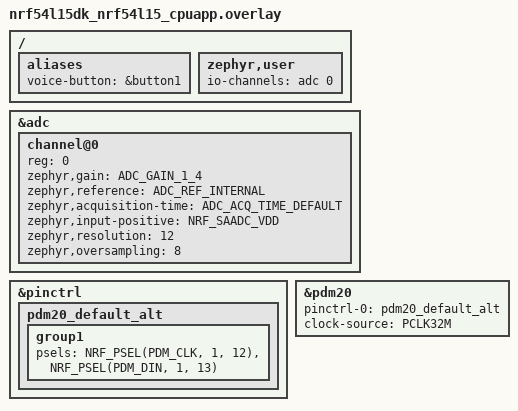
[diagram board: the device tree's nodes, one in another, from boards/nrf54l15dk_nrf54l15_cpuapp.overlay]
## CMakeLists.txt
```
cmake_minimum_required(VERSION 3.20.0)

find_package(Zephyr REQUIRED HINTS $ENV{ZEPHYR_BASE})
project(mi_remote_voice_remote)

target_sources(app PRIVATE
  src/main.c
  src/hid.c
  src/atvv_service.c
  src/audio.c
  src/battery.c
  src/battery_level.c
  src/remote_sm.c
  src/atvv_proto.c
  src/adpcm.c
  src/wake.c
)
```

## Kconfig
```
menu "MiRemoteVoice remote"

choice APP_AUDIO_SOURCE
	prompt "Audio source"
	default APP_AUDIO_SOURCE_TONE

config APP_AUDIO_SOURCE_TONE
	bool "1 kHz test tone"
	help
	  Stream a generated tone instead of the microphone. Useful for
	  checking the Bluetooth and ADPCM path on a board without a mic.

config APP_AUDIO_SOURCE_DMIC
	bool "PDM microphone (pdm20)"
	select AUDIO
	select AUDIO_DMIC

endchoice

config APP_MIC_GAIN_SHIFT
	int "Digital gain applied to microphone samples (left shift)"
	depends on APP_AUDIO_SOURCE_DMIC
	range 0 4
	default 0
	help
	  Note that mi-remote-bridge already amplifies remote audio by
	  +20 dB, so a loud microphone clips without any extra gain here.

config APP_ATVV_FRAME_SIZE
	int "ADPCM bytes per audio notification"
	range 20 244
	default 120
	help
	  Advertised to the host in the capabilities response. The actual
	  notification size is also limited by the negotiated ATT MTU.

config APP_AUDIO_TRANSFER_TIMEOUT_SECONDS
	int "Audio Transfer Timeout (s)"
	range 15 60
	default 20
	help
	  Voice over BLE spec: stop the stream if the host sends no MIC_EXTEND
	  for this long (recommended 15 s to 1 min). mi-remote-bridge sends
	  MIC_EXTEND every 4 s, Android TV every 5-10 s.

config APP_STREAM_MAX_SECONDS
	int "Maximum length of a single voice stream (s)"
	default 120
	help
	  Hard cap, e.g. for a stuck button while the host keeps extending.

config APP_ACTIVE_REMOTE_TIMEOUT_SECONDS
	int "Active Remote Timeout (s), 0 to disable"
	default 60
	help
	  Voice over BLE spec (privacy): a host MIC_OPEN is refused unless the
	  voice button was pressed within this time. Only affects hosts using
	  the On-request model; Hold-to-Talk always requires a press anyway.

config APP_BUTTON_DEBOUNCE_MS
	int "Voice button debounce time (ms)"
	default 15

config APP_AUDIO_THREAD_STACK_SIZE
	int "Audio thread stack size"
	default 2048

config APP_AUDIO_THREAD_PRIORITY
	int "Audio thread priority"
	default 5

menu "Power"

config APP_ADV_FAST_SECONDS
	int "Fast advertising after boot, disconnect or a press (s)"
	default 30

config APP_POWEROFF
	bool "Enter System OFF when idle and disconnected"
	default y
	select POWEROFF
	help
	  The voice button wakes the remote (it resets and reconnects, so the
	  waking press itself is not delivered).

config APP_POWEROFF_IDLE_SECONDS
	int "Disconnected time before System OFF (s)"
	depends on APP_POWEROFF
	default 300

endmenu

menu "Wake press"

config APP_WAKE_CAPTURE
	bool "Record and deliver the press that wakes the remote"
	default y
	help
	  If the voice button is still down when the firmware starts (it woke
	  from System OFF), record audio while reconnecting and deliver it
	  once the host is ready. See src/wake.h.

# The options below stay defined when APP_WAKE_CAPTURE is off so the code
# using them still compiles.

config APP_WAKE_BUFFER_MS
	int "Backlog length (ms)"
	range 500 5000
	default 2000
	help
	  Newest audio kept while reconnecting (8 bytes of RAM per ms).
	  mi-remote-bridge queues at most 2 s of audio, so more is not useful
	  with it.

config APP_WAKE_MIN_REPLAY_MS
	int "Minimum recording to replay a released wake press (ms)"
	default 400
	help
	  Shorter presses are treated as a tap that only wakes the remote.

config APP_WAKE_ROUTE_DELAY_MS
	int "Delay between AUDIO_START and sending the backlog (ms)"
	default 400
	help
	  mi-remote-bridge routes the remote microphone only after the key has
	  been held for 300 ms and drops audio received before that.

config APP_WAKE_TIMEOUT_SECONDS
	int "Give up if the host is not ready within (s)"
	default 10

endmenu

menu "Battery"

choice APP_BATTERY_CURVE
	prompt "Battery voltage to percentage mapping"
	default APP_BATTERY_CURVE_LINEAR

config APP_BATTERY_CURVE_LIPO
	bool "Single-cell LiPo (3.3-4.2 V)"

config APP_BATTERY_CURVE_LINEAR
	bool "Linear between APP_BATTERY_EMPTY_MV and APP_BATTERY_FULL_MV"

endchoice

config APP_BATTERY_EMPTY_MV
	int "Voltage reported as 0 %"
	depends on APP_BATTERY_CURVE_LINEAR
	default 2000

config APP_BATTERY_FULL_MV
	int "Voltage reported as 100 %"
	depends on APP_BATTERY_CURVE_LINEAR
	default 3000

config APP_BATTERY_INTERVAL_SECONDS
	int "Battery measurement interval (s)"
	default 600

endmenu

config APP_PRODUCTION_BUILD
	bool "Production build checks"
	help
	  Fail the build if the Device Information PnP VID/PID are still
	  Nordic's sample IDs.

module = APP
module-str = MiRemoteVoice remote
source "subsys/logging/Kconfig.template.log_config"

endmenu

source "Kconfig.zephyr"
```

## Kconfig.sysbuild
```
# Single-image application: no MCUboot or partition manager for now.
config PARTITION_MANAGER
	default n

source "share/sysbuild/Kconfig"
```

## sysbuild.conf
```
# MCUboot for firmware updates over Bluetooth (MCUmgr / nRF Connect Device
# Manager app).
SB_CONFIG_BOOTLOADER_MCUBOOT=y

# IMPORTANT: without this MCUboot uses the public development key from the
# MCUboot repository, so anyone could sign firmware for your remote. Generate
# your own key once and keep it private:
#   python3 <ncs>/bootloader/mcuboot/scripts/imgtool.py keygen -k priv.pem -t ed25519
# then uncomment:
# SB_CONFIG_BOOT_SIGNATURE_KEY_FILE="\${APPLICATION_CONFIG_DIR}/keys/priv.pem"
```

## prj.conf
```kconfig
# ---- Application ----
CONFIG_GPIO=y
CONFIG_ADC=y
CONFIG_LOG=y
CONFIG_APP_LOG_LEVEL_INF=y
CONFIG_MAIN_STACK_SIZE=3584
CONFIG_SYSTEM_WORKQUEUE_STACK_SIZE=2048

# ---- Bluetooth LE peripheral ----
CONFIG_BT=y
CONFIG_BT_PERIPHERAL=y
CONFIG_BT_MAX_CONN=1
CONFIG_BT_MAX_PAIRED=2
CONFIG_BT_SMP=y
CONFIG_BT_DEVICE_NAME="MiRemoteVoice"
# 961 = HID Keyboard
CONFIG_BT_DEVICE_APPEARANCE=961

# Same workaround as NCS peripheral_hids_keyboard: some laptop controllers
# collide with automatic PHY updates / security requests and disconnect.
CONFIG_BT_GATT_AUTO_SEC_REQ=n
CONFIG_BT_AUTO_PHY_UPDATE=n

# Bonds survive reboots. ZMS is the recommended settings store for the
# nRF54L RRAM; without an explicit backend Zephyr falls back to
# SETTINGS_NONE and the Mac would have to re-pair after every reset.
CONFIG_BT_SETTINGS=y
CONFIG_SETTINGS=y
CONFIG_FLASH=y
CONFIG_FLASH_MAP=y
CONFIG_ZMS=y
CONFIG_SETTINGS_ZMS=y

# Throughput for 8 kB/s of ADPCM: large MTU and data length.
CONFIG_BT_L2CAP_TX_MTU=247
CONFIG_BT_BUF_ACL_TX_SIZE=251
CONFIG_BT_BUF_ACL_RX_SIZE=251
CONFIG_BT_BUF_ACL_TX_COUNT=10
# Must exceed the ACL TX buffer count (static assert in the host).
CONFIG_BT_BUF_EVT_RX_COUNT=16
CONFIG_BT_ATT_TX_COUNT=10
CONFIG_BT_CTLR_DATA_LENGTH_MAX=251

# ---- HID over GATT (voice key) ----
CONFIG_BT_HIDS=y
CONFIG_BT_HIDS_INPUT_REP_MAX=1
CONFIG_BT_HIDS_OUTPUT_REP_MAX=1
CONFIG_BT_HIDS_FEATURE_REP_MAX=0
CONFIG_BT_HIDS_ATTR_MAX=21
CONFIG_BT_HIDS_MAX_CLIENT_COUNT=1
CONFIG_BT_HIDS_DEFAULT_PERM_RW_ENCRYPT=y
CONFIG_BT_CONN_CTX=y
CONFIG_BT_GATT_UUID16_POOL_SIZE=40
CONFIG_BT_GATT_CHRC_POOL_SIZE=20

CONFIG_BT_BAS=y

CONFIG_BT_DIS=y
CONFIG_BT_DIS_MANUF_NAME=y
CONFIG_BT_DIS_MANUF_NAME_STR="MiRemoteVoice"
CONFIG_BT_DIS_PNP=y
# USB-IF vendor ID source. 0x1915/0xEEEF are Nordic's sample IDs, fine for
# development only: replace with your own VID/PID before shipping.
CONFIG_BT_DIS_PNP_VID_SRC=2
CONFIG_BT_DIS_PNP_VID=0x1915
CONFIG_BT_DIS_PNP_PID=0xEEEF
CONFIG_BT_DIS_PNP_VER=0x0100

# ---- Firmware update over Bluetooth (MCUmgr SMP, needs MCUboot) ----
# MCUboot is enabled in sysbuild.conf. Only encrypted (paired) links may use
# the SMP service; MCUboot additionally rejects images not signed with the
# key configured in sysbuild.conf.
CONFIG_NCS_SAMPLE_MCUMGR_BT_OTA_DFU=y
CONFIG_MCUMGR_TRANSPORT_BT_PERM_RW_ENCRYPT=y
```

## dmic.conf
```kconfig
# Use the PDM microphone instead of the test tone:
#   west build ... -- -DEXTRA_CONF_FILE=dmic.conf
CONFIG_APP_AUDIO_SOURCE_DMIC=y
```

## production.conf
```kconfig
# Production build: use together with release.conf
#   west build ... -- -DEXTRA_CONF_FILE="release.conf;production.conf"
#
# The build fails until the USB-IF VID/PID below are replaced with IDs you
# own (the defaults in prj.conf are Nordic's sample IDs).
CONFIG_APP_PRODUCTION_BUILD=y
# CONFIG_BT_DIS_PNP_VID=0x....
# CONFIG_BT_DIS_PNP_PID=0x....
# CONFIG_BT_DIS_MANUF_NAME_STR="Your Company"
```

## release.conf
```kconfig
# Low-power release build: no logging or UART console (a running UART
# receiver costs hundreds of uA).
#   west build ... -- -DEXTRA_CONF_FILE=release.conf
CONFIG_LOG=n
CONFIG_SERIAL=n
CONFIG_CONSOLE=n
CONFIG_UART_CONSOLE=n
```

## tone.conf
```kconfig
# Force the 1 kHz test tone (e.g. on a XIAO without the Sense microphone).
CONFIG_APP_AUDIO_SOURCE_TONE=y
```

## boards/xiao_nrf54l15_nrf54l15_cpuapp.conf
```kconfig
# The XIAO nRF54L15 Sense has an on-board PDM microphone.
# For the plain XIAO nRF54L15 (no mic), build with -DEXTRA_CONF_FILE=tone.conf.
CONFIG_APP_AUDIO_SOURCE_DMIC=y

# Single-cell LiPo on the BAT pads.
CONFIG_APP_BATTERY_CURVE_LIPO=y
```

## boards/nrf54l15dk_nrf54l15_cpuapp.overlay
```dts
/*
 * nRF54L15 DK: the voice key is BUTTON 1 (P1.09) because BUTTON 0 (P1.13)
 * shares a pin with the external PDM microphone below.
 *
 * External PDM mic wiring (same pins as Zephyr's DMIC sample):
 *   CLK -> P1.12, DATA -> P1.13, plus VDD/GND and L/R select to GND (left).
 * Change the psels to match your wiring.
 */
/ {
	aliases {
		voice-button = &button1;
	};

	/* Battery level = supply voltage (VDD), as on a remote running directly
	 * from 2x AAA. On the DK this is the regulated VDD, not a battery. */
	zephyr,user {
		io-channels = <&adc 0>;
	};
};

&adc {
	#address-cells = <1>;
	#size-cells = <0>;
	status = "okay";

	channel@0 {
		reg = <0>;
		zephyr,gain = "ADC_GAIN_1_4";
		zephyr,reference = "ADC_REF_INTERNAL";
		zephyr,acquisition-time = <ADC_ACQ_TIME_DEFAULT>;
		zephyr,input-positive = <NRF_SAADC_VDD>;
		zephyr,resolution = <12>;
		zephyr,oversampling = <8>;
	};
};

&pinctrl {
	pdm20_default_alt: pdm20_default_alt {
		group1 {
			psels = <NRF_PSEL(PDM_CLK, 1, 12)>,
				<NRF_PSEL(PDM_DIN, 1, 13)>;
		};
	};
};

&pdm20 {
	status = "okay";
	pinctrl-0 = <&pdm20_default_alt>;
	pinctrl-names = "default";
	clock-source = "PCLK32M";
};
```

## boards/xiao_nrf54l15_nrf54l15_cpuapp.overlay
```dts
/*
 * Seeed XIAO nRF54L15 (Sense): the voice key is the USR button (alias sw0);
 * the Sense microphone (pdm20) is already described by the board.
 *
 * Battery: VBAT is read on AIN7 through a 2:1 divider that is switched on
 * by the vbat_pwr regulator (P1.15) only while measuring.
 */
/ {
	zephyr,user {
		io-channels = <&adc 7>;
		battery-divider-ratio = <2>;
		battery-enable = <&vbat_pwr>;
	};
};
```

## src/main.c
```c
/*
 * MiRemoteVoice nRF54L15 voice remote.
 *
 * A BLE HID keyboard (voice key = F5) plus the Android TV Voice (ATVV) service
 * streaming 16 kHz IMA ADPCM, compatible with mi-remote-bridge on macOS.
 *
 * Threads:
 *   main  - owns the remote_sm state machine; all events arrive via app_events
 *   audio - reads the mic (or test tone), encodes and notifies audio frames
 *
 * Power: between presses the SoC idles in System ON sleep. While
 * disconnected it advertises fast, then slowly, and finally enters System OFF
 * (a few uA); the voice button wakes it with a reset. Audio spoken while it
 * reconnects is recorded and delivered once the host is ready (wake.h).
 */
#include <string.h>

#include <zephyr/bluetooth/bluetooth.h>
#include <zephyr/bluetooth/conn.h>
#include <zephyr/bluetooth/gatt.h>
#include <zephyr/bluetooth/uuid.h>
#include <zephyr/drivers/gpio.h>
#include <zephyr/kernel.h>
#include <zephyr/logging/log.h>
#include <zephyr/logging/log_ctrl.h>
#include <zephyr/settings/settings.h>
#include <zephyr/spinlock.h>
#include <zephyr/sys/poweroff.h>

#include "app.h"
#include "atvv_proto.h"
#include "atvv_service.h"
#include "audio.h"
#include "battery.h"
#include "hid.h"
#include "remote_sm.h"
#include "wake.h"

LOG_MODULE_REGISTER(app, CONFIG_APP_LOG_LEVEL);

#if defined(CONFIG_APP_PRODUCTION_BUILD)
BUILD_ASSERT(CONFIG_BT_DIS_PNP_VID != 0x1915 || CONFIG_BT_DIS_PNP_PID != 0xEEEF,
	     "Production build still uses Nordic's sample USB VID/PID: set "
	     "CONFIG_BT_DIS_PNP_VID/PID to your own IDs (see production.conf)");
#endif

/* ---- Connection tracking. ---- */

static struct k_spinlock conn_lock;
static struct bt_conn *current_conn;

struct bt_conn *app_conn_get(void)
{
	k_spinlock_key_t key = k_spin_lock(&conn_lock);
	struct bt_conn *conn = current_conn ? bt_conn_ref(current_conn) : NULL;

	k_spin_unlock(&conn_lock, key);
	return conn;
}

void app_conn_put(struct bt_conn *conn)
{
	if (conn) {
		bt_conn_unref(conn);
	}
}

/* ---- Events for the main thread. ---- */

enum app_event_type {
	EVT_BUTTON,         /* data[0] = pressed */
	EVT_HOST_WRITE,     /* data = ATVV command */
	EVT_AUDIO_CCC,      /* data[0] = notifications enabled */
	EVT_TIMEOUT,        /* data[0] = enum remote_timeout */
	EVT_INACTIVE,       /* Active Remote Timeout expired */
	EVT_DISCONNECTED,
	EVT_SECURITY,       /* link encrypted */
	EVT_WAKE_TIMEOUT,   /* host not ready in time for the wake press */
	EVT_BACKLOG_SENT,   /* wake backlog sent (or abandoned) */
};

struct app_event {
	uint8_t type;
	uint8_t len;
	uint8_t data[8];
};

K_MSGQ_DEFINE(app_events, sizeof(struct app_event), 16, 4);

static void post_event(const struct app_event *evt)
{
	if (k_msgq_put(&app_events, evt, K_NO_WAIT)) {
		LOG_WRN("event queue full, dropped type %u", evt->type);
	}
}

/* ---- Voice button (debounced GPIO) and LED. ---- */

#if DT_NODE_HAS_STATUS(DT_ALIAS(voice_button), okay)
#define BUTTON_NODE DT_ALIAS(voice_button)
#else
#define BUTTON_NODE DT_ALIAS(sw0)
#endif

static const struct gpio_dt_spec button = GPIO_DT_SPEC_GET(BUTTON_NODE, gpios);
static const struct gpio_dt_spec led = GPIO_DT_SPEC_GET_OR(DT_ALIAS(led0), gpios, {0});
static struct gpio_callback button_cb;
static bool button_reported;

static void button_debounced(struct k_work *work)
{
	bool pressed = gpio_pin_get_dt(&button) > 0;

	if (pressed == button_reported) {
		return;
	}
	button_reported = pressed;
	post_event(&(struct app_event){.type = EVT_BUTTON, .data = {pressed}});
}

static K_WORK_DELAYABLE_DEFINE(button_work, button_debounced);

static void button_isr(const struct device *dev, struct gpio_callback *cb, uint32_t pins)
{
	k_work_reschedule(&button_work, K_MSEC(CONFIG_APP_BUTTON_DEBOUNCE_MS));
}

static int button_init(void)
{
	int err;

	if (!gpio_is_ready_dt(&button)) {
		return -ENODEV;
	}
	err = gpio_pin_configure_dt(&button, GPIO_INPUT);
	if (!err) {
		/* A press that is still down at boot is the one that woke us. */
		button_reported = gpio_pin_get_dt(&button) > 0;

		err = gpio_pin_interrupt_configure_dt(&button, GPIO_INT_EDGE_BOTH);
	}
	if (err) {
		return err;
	}
	gpio_init_callback(&button_cb, button_isr, BIT(button.pin));
	gpio_add_callback(button.port, &button_cb);

	if (led.port && gpio_is_ready_dt(&led)) {
		gpio_pin_configure_dt(&led, GPIO_OUTPUT_INACTIVE);
	}
	return 0;
}

static void set_led(bool on)
{
	if (led.port) {
		gpio_pin_set_dt(&led, on);
	}
}

/* ---- Advertising and power policy (system workqueue). ---- */

#define ATVV_SERVICE_UUID                                                                          \
	BT_UUID_128_ENCODE(ATVV_UUID_SERVICE_VAL, 0x5A21, 0x4F05, 0xBC7D, 0xAF01F617B664ULL)

/* The bridge finds the remote by the ATVV UUID in the advertisement. */
static const struct bt_data ad[] = {
	BT_DATA_BYTES(BT_DATA_FLAGS, (BT_LE_AD_GENERAL | BT_LE_AD_NO_BREDR)),
	BT_DATA_BYTES(BT_DATA_GAP_APPEARANCE, (CONFIG_BT_DEVICE_APPEARANCE >> 0) & 0xff,
		      (CONFIG_BT_DEVICE_APPEARANCE >> 8) & 0xff),
	BT_DATA_BYTES(BT_DATA_UUID16_SOME, BT_UUID_16_ENCODE(BT_UUID_HIDS_VAL)),
	BT_DATA_BYTES(BT_DATA_UUID128_SOME, ATVV_SERVICE_UUID),
};

static const struct bt_data sd[] = {
	BT_DATA(BT_DATA_NAME_COMPLETE, CONFIG_BT_DEVICE_NAME, sizeof(CONFIG_BT_DEVICE_NAME) - 1),
};

static bool is_connected(void)
{
	struct bt_conn *conn = app_conn_get();
	bool connected = conn != NULL;

	app_conn_put(conn);
	return connected;
}

static void advertise(bool fast)
{
	/* Fast: quick reconnection right after boot, disconnect or a press.
	 * Slow: cheap background advertising until System OFF. */
	const struct bt_le_adv_param *param =
		fast ? BT_LE_ADV_PARAM(BT_LE_ADV_OPT_CONN, BT_GAP_ADV_FAST_INT_MIN_1,
				       BT_GAP_ADV_FAST_INT_MAX_1, NULL)
		     : BT_LE_ADV_PARAM(BT_LE_ADV_OPT_CONN, BT_GAP_ADV_SLOW_INT_MIN,
				       BT_GAP_ADV_SLOW_INT_MAX, NULL);

	(void)bt_le_adv_stop();
	int err = bt_le_adv_start(param, ad, ARRAY_SIZE(ad), sd, ARRAY_SIZE(sd));

	if (err) {
		LOG_ERR("advertising failed: %d", err);
		return;
	}
	LOG_INF("advertising (%s)", fast ? "fast" : "slow");
}

static void adv_slow_handler(struct k_work *work)
{
	if (!is_connected()) {
		advertise(false);
	}
}

static K_WORK_DELAYABLE_DEFINE(adv_slow_work, adv_slow_handler);

static void poweroff_handler(struct k_work *work);
static K_WORK_DELAYABLE_DEFINE(poweroff_work, poweroff_handler);

/* Start (or restart) the disconnected-state timeline: fast -> slow -> off. */
static void disconnected_timeline(struct k_work *work)
{
	if (is_connected()) {
		return;
	}
	advertise(true);
	k_work_reschedule(&adv_slow_work, K_SECONDS(CONFIG_APP_ADV_FAST_SECONDS));
	if (IS_ENABLED(CONFIG_APP_POWEROFF) && CONFIG_APP_POWEROFF_IDLE_SECONDS > 0) {
		k_work_reschedule(&poweroff_work, K_SECONDS(CONFIG_APP_POWEROFF_IDLE_SECONDS));
	}
}

static K_WORK_DEFINE(timeline_work, disconnected_timeline);

static void stop_disconnected_timeline(void)
{
	k_work_cancel_delayable(&adv_slow_work);
	k_work_cancel_delayable(&poweroff_work);
}

static void poweroff_handler(struct k_work *work)
{
#if defined(CONFIG_APP_POWEROFF)
	if (is_connected()) {
		return;
	}
	LOG_INF("idle while disconnected: entering System OFF, press the voice button to wake");
	(void)bt_le_adv_stop();
	audio_stop();
	set_led(false);

	/* Level-sensitive wake-up on the voice button. */
	int err = gpio_pin_interrupt_configure_dt(&button, GPIO_INT_LEVEL_ACTIVE);

	if (err) {
		LOG_ERR("cannot arm wake-up button (%d), staying on", err);
		gpio_pin_interrupt_configure_dt(&button, GPIO_INT_EDGE_BOTH);
		return;
	}
	if (IS_ENABLED(CONFIG_LOG)) {
		log_panic(); /* flush pending log output */
	}
	sys_poweroff();
#endif
}

/* ---- Timers owned by the state machine glue. ---- */

static void transfer_timeout(struct k_work *work)
{
	post_event(&(struct app_event){.type = EVT_TIMEOUT, .data = {REMOTE_TIMEOUT_TRANSFER}});
}

static void max_duration_timeout(struct k_work *work)
{
	post_event(&(struct app_event){.type = EVT_TIMEOUT, .data = {REMOTE_TIMEOUT_MAX}});
}

static void active_timeout(struct k_work *work)
{
	post_event(&(struct app_event){.type = EVT_INACTIVE});
}

/* Spec "Audio Transfer Timeout": reset by AUDIO_START and MIC_EXTEND. */
static K_WORK_DELAYABLE_DEFINE(transfer_work, transfer_timeout);
/* Hard cap on stream length in case the button is stuck. */
static K_WORK_DELAYABLE_DEFINE(max_duration_work, max_duration_timeout);
/* Spec "Active Remote Timeout": MIC_OPEN only shortly after user activity. */
static K_WORK_DELAYABLE_DEFINE(active_work, active_timeout);

static void wake_timeout_handler(struct k_work *work)
{
	post_event(&(struct app_event){.type = EVT_WAKE_TIMEOUT});
}

static K_WORK_DELAYABLE_DEFINE(wake_timeout_work, wake_timeout_handler);

/* ---- State machine glue (runs on the main thread). ---- */

static struct remote_sm sm;
static struct wake wake;
/* The next AUDIO_START belongs to the wake press: send its backlog instead
 * of starting a fresh recording. */
static bool wake_stream_pending;
/* The wake backlog is waiting to be sent (route delay). */
static bool wake_backlog_inflight;
/* The button is already up: release the delivered press once the backlog has
 * been sent. */
static bool wake_replaying;

static void sm_send_ctl(void *ctx, const uint8_t *data, size_t len)
{
	struct bt_conn *conn = app_conn_get();
	int err = atvv_notify_ctl(conn, data, len);

	if (err && conn) {
		LOG_WRN("ctl 0x%02x not sent: %d", data[0], err);
	}
	app_conn_put(conn);
}

static void sm_hid_key(void *ctx, bool pressed)
{
	struct bt_conn *conn = app_conn_get();
	int err = hid_voice_key(conn, pressed);

	if (err && conn) {
		LOG_WRN("HID key %s not sent: %d", pressed ? "down" : "up", err);
	}
	app_conn_put(conn);
}

static void sm_audio_start(void *ctx, uint8_t codec, uint16_t frame_size)
{
	k_work_reschedule(&max_duration_work, K_SECONDS(CONFIG_APP_STREAM_MAX_SECONDS));
	set_led(true);
	if (wake_stream_pending) {
		wake_stream_pending = false;
		/* Hold the backlog back until the bridge has classified the press
		 * as a long press and routed the remote mic (300 ms); audio before
		 * that would be dropped on the Mac. */
		wake_backlog_inflight = true;
		audio_prebuffer_release(CONFIG_APP_WAKE_ROUTE_DELAY_MS);
	} else {
		audio_start(codec, frame_size);
	}
}

static void sm_audio_stop(void *ctx)
{
	if (wake_backlog_inflight) {
		/* Stream ended (timeout, MIC_CLOSE...) before the backlog went
		 * out: the audio thread will not report it, so do it here so a
		 * replayed press still gets released. */
		post_event(&(struct app_event){.type = EVT_BACKLOG_SENT});
	}
	audio_stop();
	set_led(false);
	k_work_cancel_delayable(&max_duration_work);
}

static void sm_transfer_timer(void *ctx, bool arm)
{
	if (arm) {
		k_work_reschedule(&transfer_work,
				  K_SECONDS(CONFIG_APP_AUDIO_TRANSFER_TIMEOUT_SECONDS));
	} else {
		k_work_cancel_delayable(&transfer_work);
	}
}

static void sm_user_activity(void *ctx)
{
	if (CONFIG_APP_ACTIVE_REMOTE_TIMEOUT_SECONDS > 0) {
		k_work_reschedule(&active_work, K_SECONDS(CONFIG_APP_ACTIVE_REMOTE_TIMEOUT_SECONDS));
	}
}

static const struct remote_sm_ops sm_ops = {
	.send_ctl = sm_send_ctl,
	.hid_key = sm_hid_key,
	.audio_start = sm_audio_start,
	.audio_stop = sm_audio_stop,
	.transfer_timer = sm_transfer_timer,
	.user_activity = sm_user_activity,
};

/* Keep the state machine's view of the link current before each event. */
static void refresh_link_state(void)
{
	struct bt_conn *conn = app_conn_get();

	if (conn) {
		uint16_t mtu = bt_gatt_get_mtu(conn);
		uint16_t max = CONFIG_APP_ATVV_FRAME_SIZE;

		if (mtu > 3 && mtu - 3 < max) {
			max = mtu - 3;
		}
		remote_sm_set_max_frame_size(&sm, max);
		remote_sm_audio_subscribed(&sm, atvv_audio_subscribed(conn));
	}
	app_conn_put(conn);
}

/* Bluetooth RX thread: copy the command and hand it to the main thread. */
static void on_atvv_write(const uint8_t *data, size_t len)
{
	struct app_event evt = {.type = EVT_HOST_WRITE};

	evt.len = (uint8_t)MIN(len, sizeof(evt.data));
	memcpy(evt.data, data, evt.len);
	post_event(&evt);
}

static void on_audio_ccc(bool enabled)
{
	post_event(&(struct app_event){.type = EVT_AUDIO_CCC, .data = {enabled}});
}

/* Audio thread: the wake backlog has been sent. */
static void on_backlog_sent(bool recording)
{
	ARG_UNUSED(recording);
	post_event(&(struct app_event){.type = EVT_BACKLOG_SENT});
}

/* ---- Wake press (runs on the main thread). ---- */

static const char *const wake_action_names[] = {
	"none", "freeze", "restart", "deliver hold", "deliver replay", "deliver press", "discard",
};

/* Deliver the wake press to the state machine as a (replayed) press. */
static void deliver_wake_press(bool replay)
{
	wake_stream_pending = true;
	wake_replaying = replay;
	remote_sm_button(&sm, true);

	if (wake_stream_pending) {
		/* No stream started (e.g. notifications went away): give up. */
		wake_stream_pending = false;
		audio_stop();
		if (replay) {
			wake_replaying = false;
			remote_sm_button(&sm, false);
		}
	}
}

static void apply_wake_action(enum wake_action action)
{
	if (action == WAKE_NONE) {
		return;
	}
	LOG_INF("wake press: %s (backlog %u ms)", wake_action_names[action], audio_backlog_ms());

	switch (action) {
	case WAKE_FREEZE:
		audio_prebuffer_freeze();
		break;
	case WAKE_RESTART:
		audio_prebuffer_start();
		break;
	case WAKE_DELIVER_HOLD:
		deliver_wake_press(false);
		break;
	case WAKE_DELIVER_REPLAY:
		deliver_wake_press(true);
		break;
	case WAKE_DELIVER_PRESS:
		audio_stop();
		remote_sm_button(&sm, true);
		break;
	case WAKE_DISCARD:
		audio_stop();
		break;
	default:
		break;
	}

	if (!wake_pending(&wake)) {
		k_work_cancel_delayable(&wake_timeout_work);
	}
}

/* Deliver the wake press once the host can take it. */
static void check_wake_ready(void)
{
	if (!wake_pending(&wake)) {
		return;
	}

	struct bt_conn *conn = app_conn_get();
	bool ready = conn && bt_conn_get_security(conn) >= BT_SECURITY_L2 && sm.caps_received &&
		     sm.audio_subscribed;

	app_conn_put(conn);
	if (ready) {
		apply_wake_action(wake_ready(&wake, sm.model == ATVV_MODEL_HOLD_TO_TALK,
					     audio_backlog_ms()));
	}
}

/* ---- Connection callbacks. ---- */

static void connected(struct bt_conn *conn, uint8_t err)
{
	if (err) {
		LOG_WRN("connection failed: 0x%02x", err);
		return;
	}

	k_spinlock_key_t key = k_spin_lock(&conn_lock);

	if (current_conn) {
		/* CONFIG_BT_MAX_CONN=1 should make this unreachable. */
		k_spin_unlock(&conn_lock, key);
		bt_conn_disconnect(conn, BT_HCI_ERR_REMOTE_USER_TERM_CONN);
		return;
	}
	current_conn = bt_conn_ref(conn);
	k_spin_unlock(&conn_lock, key);

	LOG_INF("connected");
	stop_disconnected_timeline();
	hid_connected(conn);
	battery_measure();

	/* 7.5-15 ms while there is traffic; peripheral latency lets the radio
	 * skip up to 30 idle intervals between presses. */
	struct bt_le_conn_param param = BT_LE_CONN_PARAM_INIT(6, 12, 30, 400);

	bt_conn_le_param_update(conn, &param);
}

static void disconnected(struct bt_conn *conn, uint8_t reason)
{
	LOG_INF("disconnected: 0x%02x", reason);
	hid_disconnected(conn);

	k_spinlock_key_t key = k_spin_lock(&conn_lock);

	if (current_conn == conn) {
		bt_conn_unref(current_conn);
		current_conn = NULL;
	}
	k_spin_unlock(&conn_lock, key);

	post_event(&(struct app_event){.type = EVT_DISCONNECTED});
}

static void recycled(void)
{
	k_work_submit(&timeline_work);
}

static void security_changed(struct bt_conn *conn, bt_security_t level, enum bt_security_err err)
{
	if (err) {
		LOG_WRN("security failed: level %u err %d", level, err);
	} else {
		LOG_INF("security level %u", level);
		post_event(&(struct app_event){.type = EVT_SECURITY});
	}
}

BT_CONN_CB_DEFINE(conn_callbacks) = {
	.connected = connected,
	.disconnected = disconnected,
	.recycled = recycled,
	.security_changed = security_changed,
};

static void handle_event(const struct app_event *evt)
{
	switch (evt->type) {
	case EVT_BUTTON: {
		enum wake_action action;

		LOG_INF("voice button %s", evt->data[0] ? "down" : "up");
		if (evt->data[0] && !is_connected()) {
			/* Pressing while disconnected: advertise fast again and
			 * postpone System OFF. */
			k_work_submit(&timeline_work);
		}
		if (wake_button(&wake, evt->data[0], &action)) {
			apply_wake_action(action);
			break;
		}
		if (!evt->data[0] && wake_backlog_inflight && !wake_replaying) {
			/* Released during the route delay: stop recording, send what
			 * was recorded, then release (EVT_BACKLOG_SENT). */
			audio_prebuffer_freeze();
			wake_replaying = true;
			break;
		}
		refresh_link_state();
		remote_sm_button(&sm, evt->data[0]);
		break;
	}
	case EVT_HOST_WRITE:
		LOG_DBG("host cmd 0x%02x (%u bytes)", evt->data[0], evt->len);
		refresh_link_state();
		remote_sm_host_write(&sm, evt->data, evt->len);
		check_wake_ready();
		break;
	case EVT_AUDIO_CCC:
		remote_sm_audio_subscribed(&sm, evt->data[0]);
		check_wake_ready();
		break;
	case EVT_SECURITY:
		refresh_link_state();
		check_wake_ready();
		break;
	case EVT_WAKE_TIMEOUT:
		apply_wake_action(wake_timeout(&wake));
		break;
	case EVT_BACKLOG_SENT:
		wake_backlog_inflight = false;
		if (wake_replaying) {
			wake_replaying = false;
			remote_sm_button(&sm, false);
		}
		break;
	case EVT_TIMEOUT:
		LOG_WRN("stream timeout (%s)",
			evt->data[0] == REMOTE_TIMEOUT_TRANSFER ? "no MIC_EXTEND" : "max duration");
		remote_sm_timeout(&sm, evt->data[0]);
		break;
	case EVT_INACTIVE:
		remote_sm_set_active(&sm, false);
		break;
	case EVT_DISCONNECTED:
		wake_stream_pending = false;
		wake_backlog_inflight = false;
		wake_replaying = false;
		remote_sm_disconnected(&sm);
		break;
	default:
		break;
	}
}

int main(void)
{
	int err;

	LOG_INF("MiRemoteVoice remote starting");

	err = button_init();
	if (err) {
		LOG_ERR("button init failed: %d", err);
		return 0;
	}

	err = audio_init(on_backlog_sent);
	if (err) {
		LOG_ERR("audio init failed: %d", err);
		return 0;
	}

	wake_init(&wake, IS_ENABLED(CONFIG_APP_WAKE_CAPTURE) && button_reported,
		  CONFIG_APP_WAKE_MIN_REPLAY_MS);
	if (wake_pending(&wake)) {
		LOG_INF("woken by the voice button: recording until the host is ready");
		audio_prebuffer_start();
		k_work_reschedule(&wake_timeout_work, K_SECONDS(CONFIG_APP_WAKE_TIMEOUT_SECONDS));
	}

	remote_sm_init(&sm, &sm_ops, NULL);
	if (CONFIG_APP_ACTIVE_REMOTE_TIMEOUT_SECONDS == 0) {
		remote_sm_set_active(&sm, true); /* timeout disabled */
	}
	atvv_service_init(on_atvv_write, on_audio_ccc);

	err = hid_init();
	if (err) {
		LOG_ERR("HID init failed: %d", err);
		return 0;
	}

	err = bt_enable(NULL);
	if (err) {
		LOG_ERR("bt_enable failed: %d", err);
		return 0;
	}

	if (IS_ENABLED(CONFIG_SETTINGS)) {
		settings_load();
	}

	/* Battery reporting is optional; keep going without it. */
	(void)battery_init();

	k_work_submit(&timeline_work);

	for (;;) {
		struct app_event evt;

		k_msgq_get(&app_events, &evt, K_FOREVER);
		handle_event(&evt);
	}
	return 0;
}
```

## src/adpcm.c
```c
/*
 * IMA/DVI ADPCM encoder. The quantisation and state update mirror
 * mi-remote-bridge/Sources/MiRemoteBridge/ATVV/ADPCMDecoder.swift exactly, so
 * the encoder's predictor always equals the decoder's output sample.
 */
#include "adpcm.h"

static const int8_t index_table[8] = {-1, -1, -1, -1, 2, 4, 6, 8};

static const int16_t step_table[89] = {
	7,     8,     9,     10,    11,    12,    13,    14,    16,    17,    19,    21,    23,
	25,    28,    31,    34,    37,    41,    45,    50,    55,    60,    66,    73,    80,
	88,    97,    107,   118,   130,   143,   157,   173,   190,   209,   230,   253,   279,
	307,   337,   371,   408,   449,   494,   544,   598,   658,   724,   796,   876,   963,
	1060,  1166,  1282,  1411,  1552,  1707,  1878,  2066,  2272,  2494,  2740,  3008,  3307,
	3638,  4002,  4402,  4842,  5327,  5860,  6446,  7091,  7800,  8580,  9438,  10382, 11420,
	12562, 13818, 15200, 16720, 18392, 20231, 22254, 24479, 26927, 29620, 32767,
};

void adpcm_reset(struct adpcm_state *state)
{
	state->predictor = 0;
	state->step_index = 0;
}

uint8_t adpcm_encode_sample(struct adpcm_state *state, int16_t sample)
{
	int step = step_table[state->step_index];
	int diff = (int)sample - (int)state->predictor;
	uint8_t code = 0;

	if (diff < 0) {
		code = 8;
		diff = -diff;
	}

	/* Same reconstruction as the decoder: step/8 + step + step/2 + step/4. */
	int delta = step >> 3;

	if (diff >= step) {
		code |= 4;
		diff -= step;
		delta += step;
	}
	if (diff >= (step >> 1)) {
		code |= 2;
		diff -= step >> 1;
		delta += step >> 1;
	}
	if (diff >= (step >> 2)) {
		code |= 1;
		delta += step >> 2;
	}

	int predictor = state->predictor + ((code & 8) ? -delta : delta);

	if (predictor > INT16_MAX) {
		predictor = INT16_MAX;
	} else if (predictor < INT16_MIN) {
		predictor = INT16_MIN;
	}
	state->predictor = (int16_t)predictor;

	int index = state->step_index + index_table[code & 7];

	if (index < 0) {
		index = 0;
	} else if (index > 88) {
		index = 88;
	}
	state->step_index = (uint8_t)index;

	return code;
}

void adpcm_encode(struct adpcm_state *state, const int16_t *samples, size_t count,
		  uint8_t *out)
{
	for (size_t i = 0; i + 1 < count; i += 2) {
		uint8_t hi = adpcm_encode_sample(state, samples[i]);
		uint8_t lo = adpcm_encode_sample(state, samples[i + 1]);

		out[i / 2] = (uint8_t)((hi << 4) | lo);
	}
}
```

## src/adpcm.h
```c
/*
 * IMA/DVI ADPCM encoder matching mi-remote-bridge's ADPCMDecoder.swift.
 *
 * Portable C with no Zephyr dependencies so it can be unit-tested on the host
 * (see tests/host).
 */
#ifndef ADPCM_H_
#define ADPCM_H_

#include <stddef.h>
#include <stdint.h>

struct adpcm_state {
	int16_t predictor;
	uint8_t step_index;
};

void adpcm_reset(struct adpcm_state *state);

/* Encode one sample and return its 4-bit code. */
uint8_t adpcm_encode_sample(struct adpcm_state *state, int16_t sample);

/*
 * Encode `count` samples (must be even) into count / 2 bytes.
 *
 * Nibble order is HIGH nibble first: byte = (code[n] << 4) | code[n + 1].
 * This is what the Mac bridge decodes; many IMA libraries use the opposite
 * order, so do not swap in a third-party encoder without checking this.
 */
void adpcm_encode(struct adpcm_state *state, const int16_t *samples, size_t count,
		  uint8_t *out);

#endif /* ADPCM_H_ */
```

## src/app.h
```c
/* Shared application state. */
#ifndef APP_H_
#define APP_H_

#include <zephyr/bluetooth/conn.h>

/* Take a reference to the current connection (NULL if none). Always pair with
 * app_conn_put(), which accepts NULL. Safe from any thread. */
struct bt_conn *app_conn_get(void);
void app_conn_put(struct bt_conn *conn);

#endif /* APP_H_ */
```

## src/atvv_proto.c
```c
#include "atvv_proto.h"

#include <string.h>

static void put_be16(uint8_t *buf, uint16_t value)
{
	buf[0] = (uint8_t)(value >> 8);
	buf[1] = (uint8_t)(value & 0xFF);
}

size_t atvv_build_caps_resp(uint8_t *buf, uint8_t codec, uint8_t model, uint16_t frame_size,
			    uint8_t extra_config)
{
	/* 0B | version 1.0 | codecs | interaction model | frame size | extra | rfu */
	buf[0] = ATVV_CTL_GET_CAPS_RESP;
	buf[1] = 0x01;
	buf[2] = 0x00;
	buf[3] = codec;
	buf[4] = model;
	put_be16(&buf[5], frame_size);
	buf[7] = extra_config;
	buf[8] = 0x00;
	return ATVV_CAPS_RESP_LEN;
}

size_t atvv_build_audio_start(uint8_t *buf, uint8_t reason, uint8_t codec, uint8_t stream_id)
{
	buf[0] = ATVV_CTL_AUDIO_START;
	buf[1] = reason;
	buf[2] = codec;
	buf[3] = stream_id;
	return ATVV_AUDIO_START_LEN;
}

size_t atvv_build_audio_sync(uint8_t *buf, uint8_t codec, uint16_t frame_num,
			     const struct adpcm_state *state)
{
	buf[0] = ATVV_CTL_AUDIO_SYNC;
	buf[1] = codec;
	put_be16(&buf[2], frame_num);
	put_be16(&buf[4], (uint16_t)state->predictor);
	buf[6] = state->step_index;
	return ATVV_AUDIO_SYNC_LEN;
}

size_t atvv_build_audio_stop(uint8_t *buf, uint8_t reason)
{
	buf[0] = ATVV_CTL_AUDIO_STOP;
	buf[1] = reason;
	return ATVV_AUDIO_STOP_LEN;
}

size_t atvv_build_start_search(uint8_t *buf)
{
	buf[0] = ATVV_CTL_START_SEARCH;
	return ATVV_START_SEARCH_LEN;
}

size_t atvv_build_mic_open_error(uint8_t *buf, uint16_t code)
{
	buf[0] = ATVV_CTL_MIC_OPEN_ERROR;
	put_be16(&buf[1], code);
	return ATVV_MIC_OPEN_ERR_LEN;
}

struct atvv_cmd atvv_parse_cmd(const uint8_t *data, size_t len)
{
	struct atvv_cmd cmd = {0};

	if (len == 0) {
		return cmd;
	}

	cmd.opcode = data[0];
	switch (cmd.opcode) {
	case ATVV_CMD_GET_CAPS:
		/* version(2) | legacy 0x0003(2) | supported interaction models(1).
		 * Hosts that omit the models field only support On-request. */
		cmd.host_models = len > 5 ? data[5] : ATVV_MODEL_ON_REQUEST;
		cmd.valid = true;
		break;
	case ATVV_CMD_MIC_OPEN:
		cmd.valid = true;
		break;
	case ATVV_CMD_MIC_CLOSE:
	case ATVV_CMD_MIC_EXTEND:
		/* v1.0 carries the stream id; v0.4 hosts send the bare opcode,
		 * which can only mean the current stream. */
		cmd.stream_id = len > 1 ? data[1] : ATVV_STREAM_ID_ANY;
		cmd.valid = true;
		break;
	default:
		break;
	}
	return cmd;
}

void atvv_framer_init(struct atvv_framer *f, const struct atvv_framer_ops *ops, void *ctx)
{
	memset(f, 0, sizeof(*f));
	f->ops = ops;
	f->ctx = ctx;
	f->frame_size = ATVV_FRAME_MAX;
}

void atvv_framer_start(struct atvv_framer *f, uint8_t codec, uint16_t frame_size)
{
	if (frame_size < 1) {
		frame_size = 1;
	} else if (frame_size > ATVV_FRAME_MAX) {
		frame_size = ATVV_FRAME_MAX;
	}

	adpcm_reset(&f->enc);
	f->frame_start = f->enc;
	f->codec = codec;
	f->frame_size = frame_size;
	f->fill = 0;
	f->frame_num = 0;
	f->resync_pending = true;
	f->have_odd = false;
	f->holding = false;
	f->count = 0;
	f->frames_sent = 0;
	f->frames_dropped = 0;
	f->backlog_dropped = 0;
}

/* Send one frame; `start`/`num` describe it for a possible AUDIO_SYNC. */
static void framer_send(struct atvv_framer *f, const uint8_t *data, size_t len,
			const struct adpcm_state *start, uint16_t num)
{
	bool send = true;

	if (f->resync_pending) {
		uint8_t sync[ATVV_AUDIO_SYNC_LEN];
		size_t sync_len = atvv_build_audio_sync(sync, f->codec, num, start);

		if (f->ops->send_ctl(f->ctx, sync, sync_len) == 0) {
			f->resync_pending = false;
		} else {
			/* The host would decode this frame with stale state: drop it
			 * and try the sync again before the next one. */
			send = false;
		}
	}

	if (send && f->ops->send_audio(f->ctx, data, len) == 0) {
		f->frames_sent++;
	} else {
		f->frames_dropped++;
		f->resync_pending = true;
	}
}

/* Backlog slot layout: predictor(2) step(1) pad(1) num(2) len(2) data. */
static uint8_t *slot_at(struct atvv_framer *f, size_t index)
{
	return f->backlog + ((f->head + index) % f->slots) * f->slot_size;
}

static void backlog_store(struct atvv_framer *f)
{
	if (f->count == f->slots) {
		/* Drop the oldest frame; the host must resync after the gap. */
		f->head = (f->head + 1) % f->slots;
		f->count--;
		f->backlog_dropped++;
		f->resync_pending = true;
	}

	uint8_t *slot = slot_at(f, f->count);
	uint16_t len = f->fill;

	memcpy(&slot[0], &f->frame_start.predictor, 2);
	slot[2] = f->frame_start.step_index;
	slot[3] = 0;
	memcpy(&slot[4], &f->frame_num, 2);
	memcpy(&slot[6], &len, 2);
	memcpy(&slot[8], f->buf, len);
	f->count++;
}

static void framer_emit(struct atvv_framer *f)
{
	if (f->holding) {
		backlog_store(f);
	} else {
		framer_send(f, f->buf, f->fill, &f->frame_start, f->frame_num);
	}
	f->frame_num++;
	f->fill = 0;
}

void atvv_framer_push(struct atvv_framer *f, const int16_t *samples, size_t count)
{
	for (size_t i = 0; i < count; i++) {
		if (!f->have_odd) {
			f->odd_sample = samples[i];
			f->have_odd = true;
			continue;
		}
		f->have_odd = false;

		if (f->fill == 0) {
			f->frame_start = f->enc;
		}

		int16_t pair[2] = {f->odd_sample, samples[i]};

		adpcm_encode(&f->enc, pair, 2, &f->buf[f->fill]);
		f->fill++;

		if (f->fill >= f->frame_size) {
			framer_emit(f);
		}
	}
}

void atvv_framer_hold(struct atvv_framer *f, void *mem, size_t mem_size)
{
	f->backlog = mem;
	f->slot_size = ATVV_BACKLOG_SLOT_SIZE(f->frame_size);
	f->slots = mem_size / f->slot_size;
	f->head = 0;
	f->count = 0;
	f->backlog_dropped = 0;
	f->holding = f->slots > 0;
}

void atvv_framer_flush_partial(struct atvv_framer *f)
{
	f->have_odd = false;
	if (f->fill > 0) {
		framer_emit(f);
	}
}

void atvv_framer_release(struct atvv_framer *f)
{
	if (!f->holding) {
		return;
	}
	f->holding = false;

	for (size_t i = 0; i < f->count; i++) {
		const uint8_t *slot = slot_at(f, i);
		struct adpcm_state start;
		uint16_t num;
		uint16_t len;

		memcpy(&start.predictor, &slot[0], 2);
		start.step_index = slot[2];
		memcpy(&num, &slot[4], 2);
		memcpy(&len, &slot[6], 2);
		framer_send(f, &slot[8], len, &start, num);
	}
	f->count = 0;
}

size_t atvv_framer_backlog_bytes(const struct atvv_framer *f)
{
	size_t bytes = 0;

	for (size_t i = 0; i < f->count; i++) {
		const uint8_t *slot = f->backlog + ((f->head + i) % f->slots) * f->slot_size;
		uint16_t len;

		memcpy(&len, &slot[6], 2);
		bytes += len;
	}
	return bytes;
}
```

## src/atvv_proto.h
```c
/*
 * Android TV Voice over BLE (ATVV) v1.0 message encoding, as consumed by
 * mi-remote-bridge/Sources/MiRemoteBridge/ATVV/ATVVProtocol.swift.
 *
 * Portable C with no Zephyr dependencies so it can be unit-tested on the host.
 */
#ifndef ATVV_PROTO_H_
#define ATVV_PROTO_H_

#include <stdbool.h>
#include <stddef.h>
#include <stdint.h>

#include "adpcm.h"

/* 128-bit UUIDs: AB5E000x-5A21-4F05-BC7D-AF01F617B664 */
#define ATVV_UUID_SERVICE_VAL 0xAB5E0001
#define ATVV_UUID_TX_VAL      0xAB5E0002 /* host -> remote commands (write) */
#define ATVV_UUID_AUDIO_VAL   0xAB5E0003 /* remote -> host audio (notify) */
#define ATVV_UUID_CTL_VAL     0xAB5E0004 /* remote -> host control (notify) */

/* Host -> remote opcodes (written to the TX characteristic). */
#define ATVV_CMD_GET_CAPS   0x0A
#define ATVV_CMD_MIC_OPEN   0x0C
#define ATVV_CMD_MIC_CLOSE  0x0D
#define ATVV_CMD_MIC_EXTEND 0x0E

/* Remote -> host opcodes (notified on the CTL characteristic). */
#define ATVV_CTL_AUDIO_STOP     0x00
#define ATVV_CTL_AUDIO_START    0x04
#define ATVV_CTL_START_SEARCH   0x08
#define ATVV_CTL_AUDIO_SYNC     0x0A
#define ATVV_CTL_GET_CAPS_RESP  0x0B
#define ATVV_CTL_MIC_OPEN_ERROR 0x0C

#define ATVV_CODEC_ADPCM_8K  0x01
#define ATVV_CODEC_ADPCM_16K 0x02

/*
 * Values below are from Google "Voice over BLE" spec v1.0.
 */

/* Assistant interaction models (GET_CAPS: supported set; CAPS_RESP: chosen). */
#define ATVV_MODEL_ON_REQUEST   0x00
#define ATVV_MODEL_PRESS_TO_TALK 0x01
#define ATVV_MODEL_HOLD_TO_TALK 0x03

/* CAPS_RESP "extra configuration". */
#define ATVV_CAPS_EXTRA_DLE 0x01 /* ask the host to enable DLE / larger MTU */

/* AUDIO_START reason. */
#define ATVV_START_REASON_MIC_OPEN     0x00
#define ATVV_START_REASON_PRESS_TO_TALK 0x01
#define ATVV_START_REASON_HOLD_TO_TALK 0x03

/* AUDIO_STOP reason. */
#define ATVV_STOP_REASON_MIC_CLOSE       0x00
#define ATVV_STOP_REASON_HTT_RELEASED    0x02
#define ATVV_STOP_REASON_UPCOMING_START  0x04
#define ATVV_STOP_REASON_TRANSFER_TIMEOUT 0x08
#define ATVV_STOP_REASON_NOTIFY_DISABLED 0x10
#define ATVV_STOP_REASON_OTHER           0x80

/* MIC_OPEN_ERROR codes. */
#define ATVV_MIC_OPEN_ERR_NOT_ACTIVE      0x0F02 /* Active Remote Timeout expired */
#define ATVV_MIC_OPEN_ERR_NOTIFY_DISABLED 0x0F03 /* audio notifications off */
#define ATVV_MIC_OPEN_ERR_PTT_HTT_ACTIVE  0x0F80 /* PTT/HTT stream in progress */
#define ATVV_MIC_OPEN_ERR_INTERNAL        0x0FFF

/* Stream ids: 0x00 = opened by MIC_OPEN, 0x01..0x80 = PTT/HTT, 0xFF = any
 * (MIC_CLOSE / MIC_EXTEND only). */
#define ATVV_STREAM_ID_MIC_OPEN 0x00
#define ATVV_STREAM_ID_HTT_MIN  0x01
#define ATVV_STREAM_ID_HTT_MAX  0x80
#define ATVV_STREAM_ID_ANY      0xFF

/* Default audio frame size before CAPS negotiation. */
#define ATVV_DEFAULT_FRAME_SIZE 20

#define ATVV_CAPS_RESP_LEN    9
#define ATVV_AUDIO_START_LEN  4
#define ATVV_AUDIO_SYNC_LEN   7
#define ATVV_AUDIO_STOP_LEN   2
#define ATVV_START_SEARCH_LEN 1
#define ATVV_MIC_OPEN_ERR_LEN 3
#define ATVV_CTL_MAX_LEN      9

size_t atvv_build_caps_resp(uint8_t *buf, uint8_t codec, uint8_t model, uint16_t frame_size,
			    uint8_t extra_config);
size_t atvv_build_audio_start(uint8_t *buf, uint8_t reason, uint8_t codec, uint8_t stream_id);
size_t atvv_build_audio_sync(uint8_t *buf, uint8_t codec, uint16_t frame_num,
			     const struct adpcm_state *state);
size_t atvv_build_audio_stop(uint8_t *buf, uint8_t reason);
size_t atvv_build_start_search(uint8_t *buf);
size_t atvv_build_mic_open_error(uint8_t *buf, uint16_t code);

struct atvv_cmd {
	uint8_t opcode;      /* one of ATVV_CMD_*, or the raw byte if unknown */
	uint8_t stream_id;   /* MIC_CLOSE / MIC_EXTEND: stream id, ANY if absent */
	uint8_t host_models; /* GET_CAPS: supported interaction models */
	bool valid;
};

struct atvv_cmd atvv_parse_cmd(const uint8_t *data, size_t len);

/*
 * Framer: turns 16-bit PCM into fixed-size ADPCM notifications.
 *
 * When a notification cannot be sent, the host decoder loses sync with the
 * encoder. The framer then sends AUDIO_SYNC (carrying the encoder state at the
 * start of the next frame) before that frame, so the host can resynchronise.
 */
#define ATVV_FRAME_MAX 244 /* max ATT payload with a 247-byte MTU */

struct atvv_framer_ops {
	/* Return 0 on success, negative if the notification was not queued. */
	int (*send_audio)(void *ctx, const uint8_t *data, size_t len);
	int (*send_ctl)(void *ctx, const uint8_t *data, size_t len);
};

struct atvv_framer {
	const struct atvv_framer_ops *ops;
	void *ctx;
	struct adpcm_state enc;
	struct adpcm_state frame_start;
	uint8_t codec;
	uint16_t frame_size;
	uint16_t fill;
	uint16_t frame_num;
	bool resync_pending;
	bool have_odd;
	int16_t odd_sample;
	uint8_t buf[ATVV_FRAME_MAX];
	/* Backlog ring used while holding (see atvv_framer_hold). */
	bool holding;
	uint8_t *backlog;
	size_t slot_size;
	size_t slots;
	size_t head;  /* oldest stored frame */
	size_t count; /* stored frames */
	/* Statistics. */
	uint32_t frames_sent;
	uint32_t frames_dropped;
	uint32_t backlog_dropped;
};

void atvv_framer_init(struct atvv_framer *f, const struct atvv_framer_ops *ops, void *ctx);
/*
 * Reset encoder and counters for a new stream. frame_size (bytes per
 * notification) is clamped to [1, ATVV_FRAME_MAX]. The first frame of every
 * stream is preceded by an AUDIO_SYNC carrying the initial encoder state.
 */
void atvv_framer_start(struct atvv_framer *f, uint8_t codec, uint16_t frame_size);
void atvv_framer_push(struct atvv_framer *f, const int16_t *samples, size_t count);

/*
 * Holding: complete frames are kept in a ring in `mem` instead of being sent,
 * e.g. while the remote is still reconnecting. When the ring is full the
 * oldest frame is dropped. Call after atvv_framer_start().
 */
#define ATVV_BACKLOG_SLOT_SIZE(frame_size) (8 + (size_t)(frame_size))
void atvv_framer_hold(struct atvv_framer *f, void *mem, size_t mem_size);
/* Emit the current partial frame (a trailing odd sample is dropped). */
void atvv_framer_flush_partial(struct atvv_framer *f);
/* Send the backlog (preceded by AUDIO_SYNC) and continue live. */
void atvv_framer_release(struct atvv_framer *f);
size_t atvv_framer_backlog_bytes(const struct atvv_framer *f);

#endif /* ATVV_PROTO_H_ */
```

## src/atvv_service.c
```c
#include "atvv_service.h"

#include <errno.h>
#include <zephyr/bluetooth/gatt.h>
#include <zephyr/bluetooth/uuid.h>
#include <zephyr/logging/log.h>

#include "atvv_proto.h"

LOG_MODULE_REGISTER(atvv, CONFIG_APP_LOG_LEVEL);

#define ATVV_UUID(val) BT_UUID_128_ENCODE(val, 0x5A21, 0x4F05, 0xBC7D, 0xAF01F617B664ULL)

static const struct bt_uuid_128 svc_uuid = BT_UUID_INIT_128(ATVV_UUID(ATVV_UUID_SERVICE_VAL));
static const struct bt_uuid_128 tx_uuid = BT_UUID_INIT_128(ATVV_UUID(ATVV_UUID_TX_VAL));
static const struct bt_uuid_128 audio_uuid = BT_UUID_INIT_128(ATVV_UUID(ATVV_UUID_AUDIO_VAL));
static const struct bt_uuid_128 ctl_uuid = BT_UUID_INIT_128(ATVV_UUID(ATVV_UUID_CTL_VAL));

static atvv_write_cb_t write_cb;
static atvv_audio_ccc_cb_t audio_ccc_cb;

static ssize_t tx_write(struct bt_conn *conn, const struct bt_gatt_attr *attr, const void *buf,
			uint16_t len, uint16_t offset, uint8_t flags)
{
	if (offset != 0) {
		return BT_GATT_ERR(BT_ATT_ERR_INVALID_OFFSET);
	}
	if (write_cb) {
		write_cb(buf, len);
	}
	return len;
}

static void audio_ccc_changed(const struct bt_gatt_attr *attr, uint16_t value)
{
	LOG_DBG("audio CCC = 0x%04x", value);
	if (audio_ccc_cb) {
		audio_ccc_cb(value & BT_GATT_CCC_NOTIFY);
	}
}

static void ctl_ccc_changed(const struct bt_gatt_attr *attr, uint16_t value)
{
	LOG_DBG("control CCC = 0x%04x", value);
}

/*
 * Encryption is required so the Mac pairs once (as a keyboard) and every later
 * connection is bonded. Attribute indices below are used by the notify helpers.
 */
BT_GATT_SERVICE_DEFINE(atvv_svc,
	BT_GATT_PRIMARY_SERVICE(&svc_uuid),
	/* [1,2] TX: host -> remote commands */
	BT_GATT_CHARACTERISTIC(&tx_uuid.uuid, BT_GATT_CHRC_WRITE | BT_GATT_CHRC_WRITE_WITHOUT_RESP,
			       BT_GATT_PERM_WRITE_ENCRYPT, NULL, tx_write, NULL),
	/* [3,4,5] AUDIO: remote -> host ADPCM */
	BT_GATT_CHARACTERISTIC(&audio_uuid.uuid, BT_GATT_CHRC_NOTIFY, BT_GATT_PERM_NONE, NULL,
			       NULL, NULL),
	BT_GATT_CCC(audio_ccc_changed, BT_GATT_PERM_READ | BT_GATT_PERM_WRITE_ENCRYPT),
	/* [6,7,8] CTL: remote -> host control events */
	BT_GATT_CHARACTERISTIC(&ctl_uuid.uuid, BT_GATT_CHRC_NOTIFY, BT_GATT_PERM_NONE, NULL,
			       NULL, NULL),
	BT_GATT_CCC(ctl_ccc_changed, BT_GATT_PERM_READ | BT_GATT_PERM_WRITE_ENCRYPT),
);

#define AUDIO_ATTR (&atvv_svc.attrs[4])
#define CTL_ATTR   (&atvv_svc.attrs[7])

void atvv_service_init(atvv_write_cb_t on_write, atvv_audio_ccc_cb_t on_audio_ccc)
{
	write_cb = on_write;
	audio_ccc_cb = on_audio_ccc;
}

bool atvv_audio_subscribed(struct bt_conn *conn)
{
	return conn && bt_gatt_is_subscribed(conn, AUDIO_ATTR, BT_GATT_CCC_NOTIFY);
}

static int notify(struct bt_conn *conn, const struct bt_gatt_attr *attr, const uint8_t *data,
		  size_t len)
{
	if (!conn) {
		return -ENOTCONN;
	}
	if (!bt_gatt_is_subscribed(conn, attr, BT_GATT_CCC_NOTIFY)) {
		return -EACCES;
	}
	return bt_gatt_notify(conn, attr, data, len);
}

int atvv_notify_ctl(struct bt_conn *conn, const uint8_t *data, size_t len)
{
	return notify(conn, CTL_ATTR, data, len);
}

int atvv_notify_audio(struct bt_conn *conn, const uint8_t *data, size_t len)
{
	return notify(conn, AUDIO_ATTR, data, len);
}
```

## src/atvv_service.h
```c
/* ATVV GATT service (UUID AB5E0001-...). */
#ifndef ATVV_SERVICE_H_
#define ATVV_SERVICE_H_

#include <stdbool.h>
#include <stddef.h>
#include <stdint.h>
#include <zephyr/bluetooth/conn.h>

/* Called from the Bluetooth RX thread for every write to the TX
 * characteristic. Must not block. */
typedef void (*atvv_write_cb_t)(const uint8_t *data, size_t len);

/* Called when the host enables or disables audio notifications. */
typedef void (*atvv_audio_ccc_cb_t)(bool enabled);

void atvv_service_init(atvv_write_cb_t on_write, atvv_audio_ccc_cb_t on_audio_ccc);
bool atvv_audio_subscribed(struct bt_conn *conn);

/* May block waiting for a TX buffer; never call from the system workqueue
 * expecting it to wait (it returns -ENOMEM there instead). */
int atvv_notify_ctl(struct bt_conn *conn, const uint8_t *data, size_t len);
int atvv_notify_audio(struct bt_conn *conn, const uint8_t *data, size_t len);

#endif /* ATVV_SERVICE_H_ */
```

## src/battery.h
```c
/* Periodic battery measurement feeding the Battery Service. */
#ifndef BATTERY_H_
#define BATTERY_H_

int battery_init(void);
/* Take a measurement now (e.g. right after a connection). */
void battery_measure(void);

#endif /* BATTERY_H_ */
```
